# PIC32CX5112MTSH128S1 register map
Vendor: Microchip Technology; Series: PIC32CXMTSH; File version: 0
CPU: CM4 r0p1, selectable endian, MPU, FPU, 4 interrupt priority bits
Registers are 32-bit, read-write, reset 0x0 unless marked. A register's access mark holds for its fields unless they carry their own. Offsets are from the block's base; [hi:lo] are bit positions; {n}, {i} and the like mark numbered series.

## CHIPID — Chip Identifier
Base 0x40050200; register names take the prefix CHIPID_
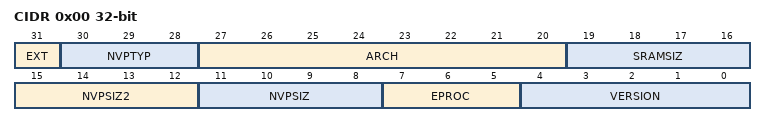
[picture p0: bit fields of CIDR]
0x00 CIDR ro — Chip ID Register
  [31] EXT — Extension Flag
  [30:28] NVPTYP — Nonvolatile Program Memory Type
    0=ROM; 1=ROMLESS (ROMless or on-chip Flash); 2=FLASH (Embedded Flash Memory); 3=ROM_FLASH (ROM and Embedded Flash Memory - NVPSIZ is ROM size - NVPSIZ2 is Flash size); 4=SRAM (SRAM emulating ROM)
  [27:20] ARCH — Architecture Identifier
    195=PIC32CXMTSH128 (Dual Core, Single Phase, High Accuracy (128-lead version)); 197=PIC32CXMTC128 (Dual Core (128-lead version)); 198=PIC32CXMTG64 (Single Core (64-lead version)); 200=PIC32CXMTG128 (Single Core (128-lead version))
  [19:16] SRAMSIZ — Internal SRAM Size
    0=_48K (48 Kbytes); 1=_192K (192 Kbytes); 2=_384K (384 Kbytes); 3=_6K (6 Kbytes); 4=_24K (24 Kbytes); 5=_4K (4 Kbytes); 6=_80K (80 Kbytes); 7=_160K (160 Kbytes); 8=_8K (8 Kbytes); 9=_16K (16 Kbytes); 10=_32K (32 Kbytes); 11=_64K (64 Kbytes); 12=_128K (128 Kbytes); 13=_256K (256 Kbytes); 14=_96K (96 Kbytes); 15=_512K (512 Kbytes)
  [15:12] NVPSIZ2 — Second Nonvolatile Program Memory Size
    0=NONE; 1=_8K (8 Kbytes); 2=_16K (16 Kbytes); 3=_32K (32 Kbytes); 5=_64K (64 Kbytes); 7=_128K (128 Kbytes); 9=_256K (256 Kbytes); 10=_512K (512 Kbytes); 12=_1024K (1024 Kbytes); 14=_2048K (2048 Kbytes)
  [11:8] NVPSIZ — Nonvolatile Program Memory Size
    0=NONE; 1=_8K (8 Kbytes); 2=_16K (16 Kbytes); 3=_32K (32 Kbytes); 5=_64K (64 Kbytes); 7=_128K (128 Kbytes); 8=_160K (160 Kbytes); 9=_256K (256 Kbytes); 10=_512K (512 Kbytes); 12=_1024K (1024 Kbytes); 14=_2048K (2048 Kbytes)
  [7:5] EPROC — Embedded Processor
    0=SAMx7 (Cortex-M7); 1=ARM946ES; 2=ARM7TDMI; 3=CM3 (Cortex-M3); 4=ARM920T; 5=ARM926EJS; 6=CA5 (Cortex-A5); 7=CM4 (Cortex-M4)
  [4:0] VERSION — Version of the Device
0x04 EXID ro — Chip ID Extension Register
  [31:0] EXID — Chip ID Extension

## GPBR — General Purpose Backup Registers
Base 0x40053060; register names take the prefix GPBR_
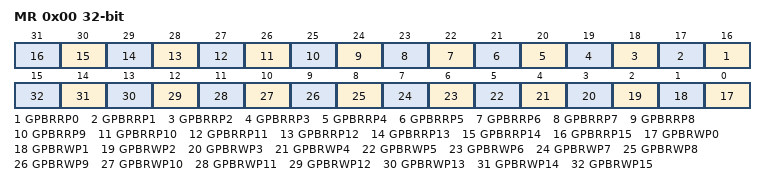
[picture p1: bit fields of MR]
0x00 MR — GPBR Mode Register
  [n+16] GPBRRP{n} (n=0..15) — GPBRx Read Protection
  [n] GPBRWP{n} (n=0..15) — GPBRx Write Protection
{0x8+4i} SYS_GPBR[{i}] (i=0..23) — General Purpose Backup Register
  [31:0] GPBR_VALUE — Value of SYS_GPBRx

## IPC0 — Inter-processor Communication
Base 0x4002C000; register names take the prefix IPC_
Same registers: IPC1 0x48014000
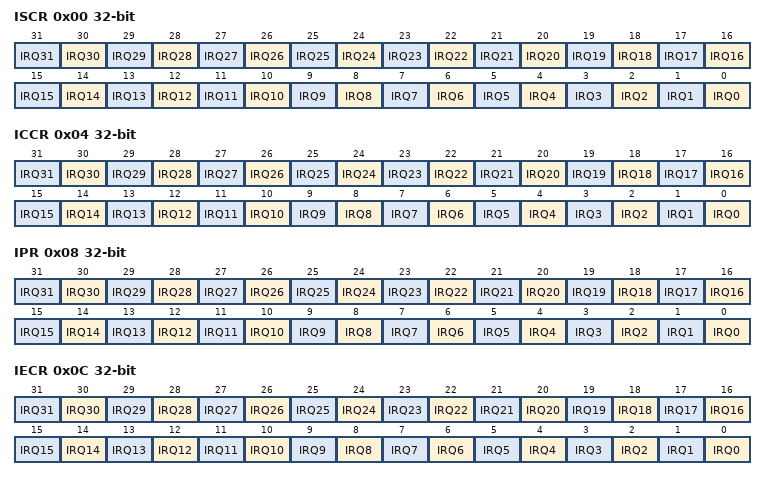
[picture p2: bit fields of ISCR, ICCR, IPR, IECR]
0x00 ISCR wo — Interrupt Set Command Register
  [n] IRQ{n} (n=0..31) — Interrupt Set
0x04 ICCR wo — Interrupt Clear Command Register
  [n] IRQ{n} (n=0..31) — Interrupt Clear
0x08 IPR ro — Interrupt Pending Register
  [n] IRQ{n} (n=0..31) — Interrupt Pending
0x0C IECR wo — Interrupt Enable Command Register
  [n] IRQ{n} (n=0..31) — Interrupt Enable
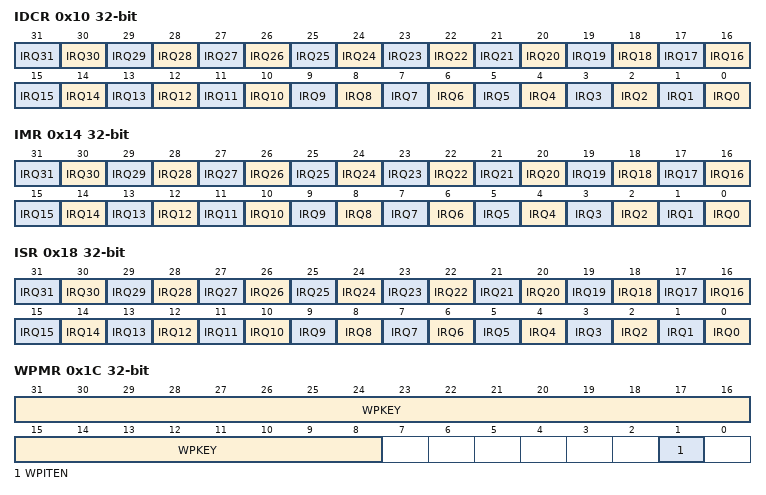
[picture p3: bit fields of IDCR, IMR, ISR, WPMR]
0x10 IDCR wo — Interrupt Disable Command Register
  [n] IRQ{n} (n=0..31) — Interrupt Disable
0x14 IMR ro — Interrupt Mask Register
  [n] IRQ{n} (n=0..31) — Interrupt Mask
0x18 ISR ro — Interrupt Status Register
  [n] IRQ{n} (n=0..31) — Current Interrupt Identifier
0x1C WPMR — Write Protection Mode Register
  [31:8] WPKEY — Write Protection Key
    0x495043=PASSWD (Writing any other value in this field aborts the write operation of the WPEN bit. Always reads as 0.)
  [1] WPITEN — Write Protection Interrupt Enable

## RSTC — Reset Controller
Base 0x40053000; register names take the prefix RSTC_
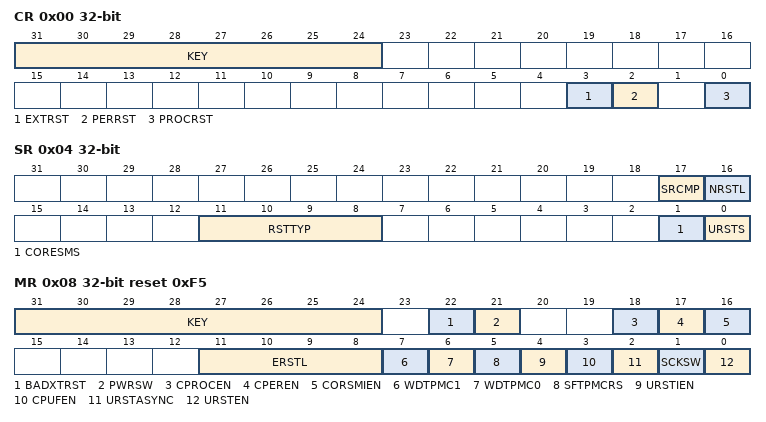
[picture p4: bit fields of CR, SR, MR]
0x00 CR wo — Control Register
  [31:24] KEY — System Reset Key
    165=PASSWD (Writing any other value in this field aborts the write operation.)
  [3] EXTRST — External Reset
  [2] PERRST — Peripheral Reset
  [0] PROCRST — Processor Reset
0x04 SR ro — Status Register
  [17] SRCMP — Software Reset Command in Progress
  [16] NRSTL — NRST Pin Level
  [11:8] RSTTYP — Reset Type
    0=GENERAL_RST (First power-up reset, Core and VDD3V3 Supply Monitor if not a PORVDD3V3 reset); 1=BACKUP_RST (VDDCORE reset. Wake-up from Backup mode); 2=WDT0_RST (Watchdog 0 fault occurred); 3=SOFT_RST (Processor reset required by the software); 4=USER_RST (NRST pin detected low); 5=CORE_SM_RST (Core Supply Monitor reset); 6=CPU_FAIL_RST (CPU clock failure detection occurred); 7=SLCK_XTAL_RST (32.768 kHz crystal failure detection fault occurred); 9=WDT1_RST (Watchdog 1 fault occurred); 10=PORVDD3V3_RST (VDD3V3 PORVDD3V3 reset occurred)
  [1] CORESMS — VDDCORE Supply Monitor Reset Flag Status (cleared on read)
  [0] URSTS — User Reset Status (cleared on read)
0x08 MR reset 0xF5 — Mode Register
  [31:24] KEY — Write Access Password
    165=PASSWD (Writing any other value in this field aborts the write operation. Always reads as 0.)
  [22] BADXTRST — Bad XTAL Fail Reset
  [21] PWRSW — Backup Area Power Switch Control
    0=VDD3V3 (VDDBU is supplied by VDD3V3); 1=VBAT (VDDBU is supplied by VBAT)
  [18] CPROCEN — Coprocessor (Second Processor) Enable
  [17] CPEREN — Coprocessor Peripheral Enable
  [16] CORSMIEN — VDDCORE Supply Monitor Interrupt Enable
  [11:8] ERSTL — External Reset Length
  [7] WDTPMC1 — WDT1 PMC Reset
  [6] WDTPMC0 — WDT0 PMC Reset
  [5] SFTPMCRS — Software PMC Reset
  [4] URSTIEN — User Reset Interrupt Enable
  [3] CPUFEN — CPU Fail Enable
  [2] URSTASYNC — User Reset Asynchronous Control
  [1] SCKSW — Slow Clock Switching
  [0] URSTEN — User Reset Enable

## Notices in the file
Copyright (c) 2017 Microchip Technology Inc.
SPDX-License-Identifier: Apache-2.0
Licensed under the Apache License, Version 2.0 (the "License");
you may not use this file except in compliance with the License.
You may obtain a copy of the License at
http://www.apache.org/licenses/LICENSE-2.0
Unless required by applicable law or agreed to in writing, software
distributed under the License is distributed on an "AS IS" BASIS,
WITHOUT WARRANTIES OR CONDITIONS OF ANY KIND, either express or implied.
See the License for the specific language governing permissions and
limitations under the License.
